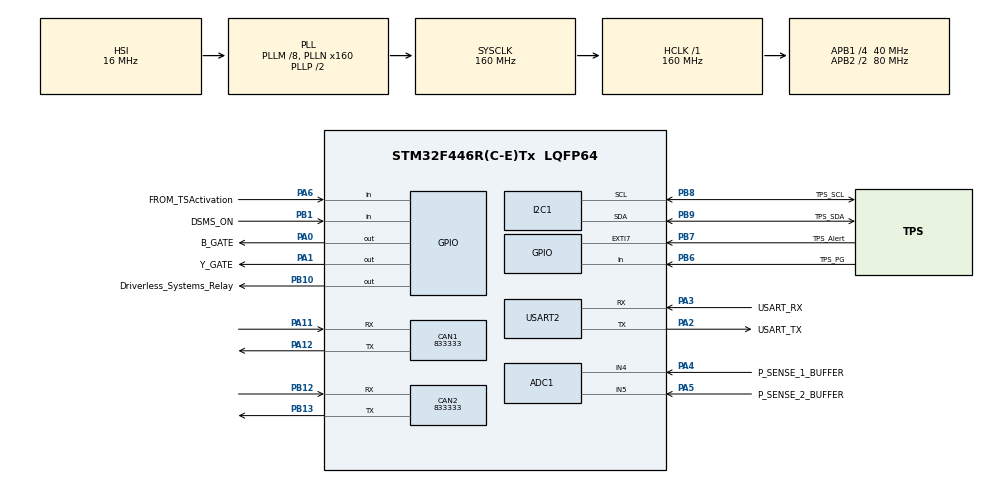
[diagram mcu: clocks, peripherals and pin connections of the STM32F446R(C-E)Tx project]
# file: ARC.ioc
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ADC1.Channel-0\#ChannelRegularConversion=ADC_CHANNEL_4
ADC1.NbrOfConversionFlag=1
ADC1.Rank-0\#ChannelRegularConversion=1
ADC1.SamplingTime-0\#ChannelRegularConversion=ADC_SAMPLETIME_3CYCLES
ADC1.master=1
CAN1.CalculateBaudRate=833333
CAN1.CalculateTimeBit=1200
CAN1.CalculateTimeQuantum=400.0
CAN2.CalculateBaudRate=833333
CAN2.CalculateTimeBit=1200
CAN2.CalculateTimeQuantum=400.0
FREERTOS.CountingSemaphores01=canTxMailboxSem,3,Dynamic,NULL,3
FREERTOS.Mutexes01=tpsI2cMutex,Dynamic,NULL,Available;canTxMutex,Dynamic,NULL,Available;canRxMutex,Dynamic,NULL,Available
FREERTOS.Queues01=Pressure_Data,1,uint16_t,0,Dynamic,NULL,NULL;State,1,uint32_t,0,Dynamic,NULL,NULL;TPS_Status,1,uint16_t,0,Dynamic,NULL,NULL;canTxQueue,16,24,1,Dynamic,NULL,NULL;canRxQueue,16,24,1,Dynamic,NULL,NULL
FREERTOS.Tasks01=K3_CONTROL,24,128,START_K3_CONTROL,Default,NULL,Dynamic,NULL,NULL;FEET_CONTROL,24,128,START_FEET_CONTROL,Default,NULL,Dynamic,NULL,NULL;P_SENSE,24,128,START_P_SENSE,Default,NULL,Dynamic,NULL,NULL;STATE_READ,24,256,START_STATE_READ,Default,NULL,Dynamic,NULL,NULL;TPS_HANDLER,24,128,StartTPSTask,Default,NULL,Dynamic,NULL,NULL
FREERTOS.configUSE_COUNTING_SEMAPHORES=1
FREERTOS.configUSE_TIMERS=1
Mcu.Family=STM32F4
Mcu.Name=STM32F446R(C-E)Tx
Mcu.Package=LQFP64
NVIC.CAN1_RX0_IRQn=true\:5\:0\:false\:false\:true\:true\:true\:true\:true
NVIC.CAN1_RX1_IRQn=true\:5\:0\:false\:false\:true\:true\:true\:true\:true
NVIC.CAN2_RX0_IRQn=true\:5\:0\:false\:false\:true\:true\:true\:true\:true
NVIC.CAN2_RX1_IRQn=true\:5\:0\:false\:false\:true\:true\:true\:true\:true
NVIC.EXTI9_5_IRQn=true\:5\:0\:false\:false\:true\:true\:true\:true\:true
NVIC.PriorityGroup=NVIC_PRIORITYGROUP_4
NVIC.TIM2_IRQn=true\:15\:0\:false\:false\:true\:false\:false\:true\:true
NVIC.TimeBase=TIM2_IRQn
NVIC.TimeBaseIP=TIM2
PA0-WKUP.GPIO_Label=B_GATE
PA0-WKUP.GPIO_PuPd=GPIO_PULLDOWN
PA0-WKUP.Signal=GPIO_Output
PA1.GPIO_Label=Y_GATE
PA1.GPIO_PuPd=GPIO_PULLDOWN
PA1.Signal=GPIO_Output
PA2.GPIO_Label=USART_TX
PA2.Mode=Asynchronous
PA2.Signal=USART2_TX
PA3.GPIO_Label=USART_RX
PA3.Mode=Asynchronous
PA3.Signal=USART2_RX
PA11.Mode=CAN_Activate
PA11.Signal=CAN1_RX
PA12.Mode=CAN_Activate
PA12.Signal=CAN1_TX
PA13.Mode=Serial_Wire
PA13.Signal=SYS_JTMS-SWDIO
PA14.Mode=Serial_Wire
PA14.Signal=SYS_JTCK-SWCLK
PA4.GPIO_Label=P_SENSE_1_BUFFER
PA4.GPIO_Mode=GPIO_MODE_ANALOG
PA4.Signal=ADCx_IN4
PA5.GPIO_Label=P_SENSE_2_BUFFER
PA5.Signal=ADCx_IN5
PA6.GPIO_Label=FROM_TSActivation
PA6.GPIO_PuPd=GPIO_PULLDOWN
PA6.Signal=GPIO_Input
PB1.GPIO_Label=DSMS_ON
PB1.Signal=GPIO_Input
PB10.GPIO_Label=Driverless_Systems_Relay
PB10.GPIO_PuPd=GPIO_NOPULL
PB10.Signal=GPIO_Output
PB12.Mode=CAN_Activate
PB12.Signal=CAN2_RX
PB13.Mode=CAN_Activate
PB13.Signal=CAN2_TX
PB6.GPIO_Label=TPS_PG
PB6.Signal=GPIO_Input
PB7.GPIO_Label=TPS_Alert
PB7.GPIO_ModeDefaultEXTI=GPIO_MODE_IT_RISING
PB7.Signal=GPXTI7
PB8.GPIO_Label=TPS_SCL
PB8.Mode=I2C
PB8.Signal=I2C1_SCL
PB9.GPIO_Label=TPS_SDA
PB9.Mode=I2C
PB9.Signal=I2C1_SDA
ProjectManager.HeapSize=0x200
ProjectManager.StackSize=0x400
ProjectManager.TargetToolchain=EWARM V8.50
RCC.AHBFreq_Value=160000000
RCC.APB1CLKDivider=RCC_HCLK_DIV4
RCC.APB1Freq_Value=40000000
RCC.APB1TimFreq_Value=80000000
RCC.APB2CLKDivider=RCC_HCLK_DIV2
RCC.APB2Freq_Value=80000000
RCC.APB2TimFreq_Value=160000000
RCC.CortexFreq_Value=160000000
RCC.HCLKFreq_Value=160000000
RCC.PLLM=8
RCC.PLLN=160
RCC.SYSCLKFreq_VALUE=160000000
RCC.SYSCLKSource=RCC_SYSCLKSOURCE_PLLCLK
RCC.USBFreq_Value=160000000
RCC.VCOOutputFreq_Value=320000000
SH.ADCx_IN4.0=ADC1_IN4,IN4
SH.ADCx_IN5.0=ADC1_IN5,IN5
USART2.VirtualMode=VM_ASYNC
VP_FREERTOS_VS_CMSIS_V2.Mode=CMSIS_V2
VP_SYS_VS_tim2.Mode=TIM2
board=custom

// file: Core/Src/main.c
/* USER CODE BEGIN Header */
/**
 ******************************************************************************
 * @file           : main.c
 * @brief          : Main program body
 ******************************************************************************
 * @attention
 *
 * Copyright (c) 2026 STMicroelectronics.
 * All rights reserved.
 *
 * This software is licensed under terms that can be found in the LICENSE file
 * in the root directory of this software component.
 * If no LICENSE file comes with this software, it is provided AS-IS.
 *
 ******************************************************************************
 */
/* USER CODE END Header */
#include "main.h"
#include "cmsis_os.h"

/* USER CODE BEGIN Includes */
#include "FEB_Main.h"
/* USER CODE END Includes */

ADC_HandleTypeDef hadc1;

CAN_HandleTypeDef hcan1;
CAN_HandleTypeDef hcan2;

I2C_HandleTypeDef hi2c1;
UART_HandleTypeDef huart2;

/* Definitions for K3_CONTROL */
osThreadId_t K3_CONTROLHandle;
const osThreadAttr_t K3_CONTROL_attributes = {
    .name = "K3_CONTROL",
    .stack_size = 1024,
    .priority = (osPriority_t)osPriorityNormal,
};
/* Definitions for FEET_CONTROL */
osThreadId_t FEET_CONTROLHandle;
const osThreadAttr_t FEET_CONTROL_attributes = {
    .name = "FEET_CONTROL",
    .stack_size = 1024,
    .priority = (osPriority_t)osPriorityNormal,
};
/* Definitions for P_SENSE */
osThreadId_t P_SENSEHandle;
const osThreadAttr_t P_SENSE_attributes = {
    .name = "P_SENSE",
    .stack_size = 1024,
    .priority = (osPriority_t)osPriorityNormal,
};
/* Definitions for STATE_READ */
osThreadId_t STATE_READHandle;
const osThreadAttr_t STATE_READ_attributes = {
    .name = "STATE_READ",
    .stack_size = 1536,
    .priority = (osPriority_t)osPriorityNormal,
};
/* Definitions for TPS_HANDLER */
osThreadId_t TPS_HANDLERHandle;
const osThreadAttr_t TPS_HANDLER_attributes = {
    .name = "TPS_HANDLER",
    .stack_size = 2048,
    .priority = (osPriority_t)osPriorityNormal,
};
/* Definitions for Pressure_Data */
osMessageQueueId_t Pressure_DataHandle;
const osMessageQueueAttr_t Pressure_Data_attributes = {.name = "Pressure_Data"};
/* Definitions for State */
osMessageQueueId_t StateHandle;
const osMessageQueueAttr_t State_attributes = {.name = "State"};
/* Definitions for TPS_Status */
osMessageQueueId_t TPS_StatusHandle;
const osMessageQueueAttr_t TPS_Status_attributes = {.name = "TPS_Status"};
/* Definitions for canTxQueue */
osMessageQueueId_t canTxQueueHandle;
const osMessageQueueAttr_t canTxQueue_attributes = {.name = "canTxQueue"};
/* Definitions for canRxQueue */
osMessageQueueId_t canRxQueueHandle;
const osMessageQueueAttr_t canRxQueue_attributes = {.name = "canRxQueue"};
/* Definitions for tpsI2cMutex */
osMutexId_t tpsI2cMutexHandle;
const osMutexAttr_t tpsI2cMutex_attributes = {.name = "tpsI2cMutex"};
osMutexId_t debugUartTxMutexHandle;
const osMutexAttr_t debugUartTxMutex_attributes = {.name = "debugUartTxMutex"};
osMutexId_t debugLogMutexHandle;
const osMutexAttr_t debugLogMutex_attributes = {.name = "debugLogMutex"};
/* Definitions for canTxMutex */
osMutexId_t canTxMutexHandle;
const osMutexAttr_t canTxMutex_attributes = {.name = "canTxMutex"};
/* Definitions for canRxMutex */
osMutexId_t canRxMutexHandle;
const osMutexAttr_t canRxMutex_attributes = {.name = "canRxMutex"};
/* Definitions for canTxMailboxSem */
osSemaphoreId_t canTxMailboxSemHandle;
const osSemaphoreAttr_t canTxMailboxSem_attributes = {.name = "canTxMailboxSem"};

void SystemClock_Config(void);
static void MX_GPIO_Init(void);
static void MX_ADC1_Init(void);
static void MX_CAN1_Init(void);
static void MX_CAN2_Init(void);
static void MX_I2C1_Init(void);
static void MX_USART2_UART_Init(void);
void START_K3_CONTROL(void *argument);
void START_FEET_CONTROL(void *argument);
void START_P_SENSE(void *argument);
void START_STATE_READ(void *argument);
void StartTPSTask(void *argument);

int main(void)
{

  /* MCU Configuration--------------------------------------------------------*/

  /* Reset of all peripherals, Initializes the Flash interface and the Systick. */
  HAL_Init();

  /* Configure the system clock */
  SystemClock_Config();

  /* Initialize all configured peripherals */
  MX_GPIO_Init();
  MX_ADC1_Init();
  MX_CAN1_Init();
  MX_CAN2_Init();
  MX_I2C1_Init();
  MX_USART2_UART_Init();

  /* Init scheduler */
  osKernelInitialize();
  /* Create the mutex(es) */
  /* creation of tpsI2cMutex */
  tpsI2cMutexHandle = osMutexNew(&tpsI2cMutex_attributes);
  debugUartTxMutexHandle = osMutexNew(&debugUartTxMutex_attributes);
  debugLogMutexHandle = osMutexNew(&debugLogMutex_attributes);

  FEB_Init();

  /* creation of canTxMutex */
  canTxMutexHandle = osMutexNew(&canTxMutex_attributes);

  /* creation of canRxMutex */
  canRxMutexHandle = osMutexNew(&canRxMutex_attributes);

  /* Create the semaphores(s) */
  /* creation of canTxMailboxSem */
  canTxMailboxSemHandle = osSemaphoreNew(3, 3, &canTxMailboxSem_attributes);

  /* Create the queue(s) */
  /* creation of Pressure_Data */
  Pressure_DataHandle = osMessageQueueNew(1, sizeof(uint16_t), &Pressure_Data_attributes);

  /* creation of State */
  StateHandle = osMessageQueueNew(1, sizeof(uint32_t), &State_attributes);

  /* creation of TPS_Status */
  TPS_StatusHandle = osMessageQueueNew(1, sizeof(uint16_t), &TPS_Status_attributes);

  /* creation of canTxQueue */
  canTxQueueHandle = osMessageQueueNew(16, 24, &canTxQueue_attributes);

  /* creation of canRxQueue */
  canRxQueueHandle = osMessageQueueNew(16, 24, &canRxQueue_attributes);

  /* Create the thread(s) */
  /* creation of K3_CONTROL */
  K3_CONTROLHandle = osThreadNew(START_K3_CONTROL, NULL, &K3_CONTROL_attributes);

  /* creation of FEET_CONTROL */
  FEET_CONTROLHandle = osThreadNew(START_FEET_CONTROL, NULL, &FEET_CONTROL_attributes);

  /* creation of P_SENSE */
  P_SENSEHandle = osThreadNew(START_P_SENSE, NULL, &P_SENSE_attributes);

  /* creation of STATE_READ */
  STATE_READHandle = osThreadNew(START_STATE_READ, NULL, &STATE_READ_attributes);

  /* creation of TPS_HANDLER */
  TPS_HANDLERHandle = osThreadNew(StartTPSTask, NULL, &TPS_HANDLER_attributes);

  /* Start scheduler */
  osKernelStart();

  /* We should never get here as control is now taken by the scheduler */

  /* Infinite loop */
  while (1)
  {

  }
}

void SystemClock_Config(void)
{
  RCC_OscInitTypeDef RCC_OscInitStruct = {0};
  RCC_ClkInitTypeDef RCC_ClkInitStruct = {0};

  /** Configure the main internal regulator output voltage
   */
  __HAL_RCC_PWR_CLK_ENABLE();
  __HAL_PWR_VOLTAGESCALING_CONFIG(PWR_REGULATOR_VOLTAGE_SCALE1);

  /** Initializes the RCC Oscillators according to the specified parameters
   * in the RCC_OscInitTypeDef structure.
   */
  RCC_OscInitStruct.OscillatorType = RCC_OSCILLATORTYPE_HSI;
  RCC_OscInitStruct.HSIState = RCC_HSI_ON;
  RCC_OscInitStruct.HSICalibrationValue = RCC_HSICALIBRATION_DEFAULT;
  RCC_OscInitStruct.PLL.PLLState = RCC_PLL_ON;
  RCC_OscInitStruct.PLL.PLLSource = RCC_PLLSOURCE_HSI;
  RCC_OscInitStruct.PLL.PLLM = 8;
  RCC_OscInitStruct.PLL.PLLN = 160;
  RCC_OscInitStruct.PLL.PLLP = RCC_PLLP_DIV2;
  RCC_OscInitStruct.PLL.PLLQ = 2;
  RCC_OscInitStruct.PLL.PLLR = 2;
  if (HAL_RCC_OscConfig(&RCC_OscInitStruct) != HAL_OK)
  {
    Error_Handler();
  }

  /** Initializes the CPU, AHB and APB buses clocks
   */
  RCC_ClkInitStruct.ClockType = RCC_CLOCKTYPE_HCLK | RCC_CLOCKTYPE_SYSCLK | RCC_CLOCKTYPE_PCLK1 | RCC_CLOCKTYPE_PCLK2;
  RCC_ClkInitStruct.SYSCLKSource = RCC_SYSCLKSOURCE_PLLCLK;
  RCC_ClkInitStruct.AHBCLKDivider = RCC_SYSCLK_DIV1;
  RCC_ClkInitStruct.APB1CLKDivider = RCC_HCLK_DIV4;
  RCC_ClkInitStruct.APB2CLKDivider = RCC_HCLK_DIV2;

  if (HAL_RCC_ClockConfig(&RCC_ClkInitStruct, FLASH_LATENCY_5) != HAL_OK)
  {
    Error_Handler();
  }
}

static void MX_ADC1_Init(void)
{

  ADC_ChannelConfTypeDef sConfig = {0};

  /** Configure the global features of the ADC (Clock, Resolution, Data Alignment and number of conversion)
   */
  hadc1.Instance = ADC1;
  hadc1.Init.ClockPrescaler = ADC_CLOCK_SYNC_PCLK_DIV4;
  hadc1.Init.Resolution = ADC_RESOLUTION_12B;
  hadc1.Init.ScanConvMode = DISABLE;
  hadc1.Init.ContinuousConvMode = DISABLE;
  hadc1.Init.DiscontinuousConvMode = DISABLE;
  hadc1.Init.ExternalTrigConvEdge = ADC_EXTERNALTRIGCONVEDGE_NONE;
  hadc1.Init.ExternalTrigConv = ADC_SOFTWARE_START;
  hadc1.Init.DataAlign = ADC_DATAALIGN_RIGHT;
  hadc1.Init.NbrOfConversion = 1;
  hadc1.Init.DMAContinuousRequests = DISABLE;
  hadc1.Init.EOCSelection = ADC_EOC_SINGLE_CONV;
  if (HAL_ADC_Init(&hadc1) != HAL_OK)
  {
    Error_Handler();
  }

  /** Configure for the selected ADC regular channel its corresponding rank in the sequencer and its sample time.
   */
  sConfig.Channel = ADC_CHANNEL_4;
  sConfig.Rank = 1;
  sConfig.SamplingTime = ADC_SAMPLETIME_3CYCLES;
  if (HAL_ADC_ConfigChannel(&hadc1, &sConfig) != HAL_OK)
  {
    Error_Handler();
  }
}

static void MX_CAN1_Init(void)
{

  hcan1.Instance = CAN1;
  hcan1.Init.Prescaler = 16;
  hcan1.Init.Mode = CAN_MODE_NORMAL;
  hcan1.Init.SyncJumpWidth = CAN_SJW_1TQ;
  hcan1.Init.TimeSeg1 = CAN_BS1_1TQ;
  hcan1.Init.TimeSeg2 = CAN_BS2_1TQ;
  hcan1.Init.TimeTriggeredMode = DISABLE;
  hcan1.Init.AutoBusOff = DISABLE;
  hcan1.Init.AutoWakeUp = DISABLE;
  hcan1.Init.AutoRetransmission = DISABLE;
  hcan1.Init.ReceiveFifoLocked = DISABLE;
  hcan1.Init.TransmitFifoPriority = DISABLE;
  if (HAL_CAN_Init(&hcan1) != HAL_OK)
  {
    Error_Handler();
  }
}

static void MX_CAN2_Init(void)
{

  hcan2.Instance = CAN2;
  hcan2.Init.Prescaler = 16;
  hcan2.Init.Mode = CAN_MODE_NORMAL;
  hcan2.Init.SyncJumpWidth = CAN_SJW_1TQ;
  hcan2.Init.TimeSeg1 = CAN_BS1_1TQ;
  hcan2.Init.TimeSeg2 = CAN_BS2_1TQ;
  hcan2.Init.TimeTriggeredMode = DISABLE;
  hcan2.Init.AutoBusOff = DISABLE;
  hcan2.Init.AutoWakeUp = DISABLE;
  hcan2.Init.AutoRetransmission = DISABLE;
  hcan2.Init.ReceiveFifoLocked = DISABLE;
  hcan2.Init.TransmitFifoPriority = DISABLE;
  if (HAL_CAN_Init(&hcan2) != HAL_OK)
  {
    Error_Handler();
  }
}

static void MX_I2C1_Init(void)
{

  hi2c1.Instance = I2C1;
  hi2c1.Init.ClockSpeed = 100000;
  hi2c1.Init.DutyCycle = I2C_DUTYCYCLE_2;
  hi2c1.Init.OwnAddress1 = 0;
  hi2c1.Init.AddressingMode = I2C_ADDRESSINGMODE_7BIT;
  hi2c1.Init.DualAddressMode = I2C_DUALADDRESS_DISABLE;
  hi2c1.Init.OwnAddress2 = 0;
  hi2c1.Init.GeneralCallMode = I2C_GENERALCALL_DISABLE;
  hi2c1.Init.NoStretchMode = I2C_NOSTRETCH_DISABLE;
  if (HAL_I2C_Init(&hi2c1) != HAL_OK)
  {
    Error_Handler();
  }
}

static void MX_USART2_UART_Init(void)
{
  huart2.Instance = USART2;
  huart2.Init.BaudRate = 115200;
  huart2.Init.WordLength = UART_WORDLENGTH_8B;
  huart2.Init.StopBits = UART_STOPBITS_1;
  huart2.Init.Parity = UART_PARITY_NONE;
  huart2.Init.Mode = UART_MODE_TX_RX;
  huart2.Init.HwFlowCtl = UART_HWCONTROL_NONE;
  huart2.Init.OverSampling = UART_OVERSAMPLING_16;
  if (HAL_UART_Init(&huart2) != HAL_OK)
  {
    Error_Handler();
  }
}

static void MX_GPIO_Init(void)
{
  GPIO_InitTypeDef GPIO_InitStruct = {0};

  /* GPIO Ports Clock Enable */
  __HAL_RCC_GPIOA_CLK_ENABLE();
  __HAL_RCC_GPIOB_CLK_ENABLE();

  /*Configure GPIO pin Output Level */
  HAL_GPIO_WritePin(GPIOA, B_GATE_Pin | Y_GATE_Pin, GPIO_PIN_RESET);

  /*Configure GPIO pin Output Level */
  HAL_GPIO_WritePin(Driverless_Systems_Relay_GPIO_Port, Driverless_Systems_Relay_Pin, GPIO_PIN_RESET);

  /*Configure GPIO pins : B_GATE_Pin Y_GATE_Pin */
  GPIO_InitStruct.Pin = B_GATE_Pin | Y_GATE_Pin;
  GPIO_InitStruct.Mode = GPIO_MODE_OUTPUT_PP;
  GPIO_InitStruct.Pull = GPIO_PULLDOWN;
  GPIO_InitStruct.Speed = GPIO_SPEED_FREQ_LOW;
  HAL_GPIO_Init(GPIOA, &GPIO_InitStruct);

  /*Configure GPIO pin : FROM_TSActivation_Pin */
  GPIO_InitStruct.Pin = FROM_TSActivation_Pin;
  GPIO_InitStruct.Mode = GPIO_MODE_INPUT;
  GPIO_InitStruct.Pull = GPIO_PULLDOWN;
  HAL_GPIO_Init(FROM_TSActivation_GPIO_Port, &GPIO_InitStruct);

  /*Configure GPIO pins : DSMS_ON_Pin TPS_PG_Pin */
  GPIO_InitStruct.Pin = DSMS_ON_Pin | TPS_PG_Pin;
  GPIO_InitStruct.Mode = GPIO_MODE_INPUT;
  GPIO_InitStruct.Pull = GPIO_NOPULL;
  HAL_GPIO_Init(GPIOB, &GPIO_InitStruct);

  /*Configure GPIO pin : Driverless_Systems_Relay_Pin */
  GPIO_InitStruct.Pin = Driverless_Systems_Relay_Pin;
  GPIO_InitStruct.Mode = GPIO_MODE_OUTPUT_PP;
  GPIO_InitStruct.Pull = GPIO_NOPULL;
  GPIO_InitStruct.Speed = GPIO_SPEED_FREQ_LOW;
  HAL_GPIO_Init(Driverless_Systems_Relay_GPIO_Port, &GPIO_InitStruct);

  /*Configure GPIO pin : TPS_Alert_Pin */
  GPIO_InitStruct.Pin = TPS_Alert_Pin;
  GPIO_InitStruct.Mode = GPIO_MODE_IT_RISING;
  GPIO_InitStruct.Pull = GPIO_NOPULL;
  HAL_GPIO_Init(TPS_Alert_GPIO_Port, &GPIO_InitStruct);

  /* EXTI interrupt init*/
  HAL_NVIC_SetPriority(EXTI9_5_IRQn, 5, 0);
  HAL_NVIC_EnableIRQ(EXTI9_5_IRQn);

}

__weak void START_K3_CONTROL(void *argument)
{
  for (;;)
  {
    osDelay(1);
  }
}

__weak void START_FEET_CONTROL(void *argument)
{
  for (;;)
  {
    osDelay(1);
  }
}

__weak void START_P_SENSE(void *argument)
{
  for (;;)
  {
    osDelay(1);
  }
}

__weak void START_STATE_READ(void *argument)
{
  for (;;)
  {
    osDelay(1);
  }
}

__weak void StartTPSTask(void *argument)
{
  for (;;)
  {
    osDelay(1);
  }
}

void HAL_TIM_PeriodElapsedCallback(TIM_HandleTypeDef *htim)
{
  if (htim->Instance == TIM2)
  {
    HAL_IncTick();
  }
}

void Error_Handler(void)
{
  __disable_irq();
  while (1)
  {
  }
}
